# PIC16F1937 register map
File version: 1.0
Registers are 8-bit, read-write, reset 0x0 unless marked. A register's access mark holds for its fields unless they carry their own. Offsets are from the block's base; [hi:lo] are bit positions; {n}, {i} and the like mark numbered series.

## MSSP — Synchronous serial port
Base 0x00800211
0x00 SSPBUF reset not defined — SSPBUF, data address 0x211
0x01 SSPADD — SSPADD, data address 0x212
0x02 SSPMSK reset 0xFF — SSPMSK, data address 0x213
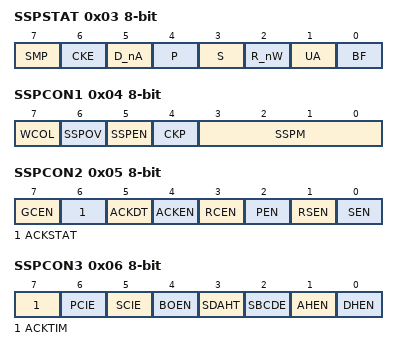
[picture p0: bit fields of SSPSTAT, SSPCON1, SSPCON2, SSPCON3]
0x03 SSPSTAT — SSPSTAT, data address 0x214
  [7] SMP, [6] CKE, [5] D_nA, [4] P, [3] S, [2] R_nW, [1] UA, [0] BF
0x04 SSPCON1 — SSPCON1, data address 0x215
  [7] WCOL, [6] SSPOV, [5] SSPEN, [4] CKP, [3:0] SSPM
0x05 SSPCON2 — SSPCON2, data address 0x216
  [7] GCEN, [6] ACKSTAT, [5] ACKDT, [4] ACKEN, [3] RCEN, [2] PEN, [1] RSEN, [0] SEN
0x06 SSPCON3 (reset mask 0x9F) — SSPCON3, data address 0x217
  [7] ACKTIM, [6] PCIE, [5] SCIE, [4] BOEN, [3] SDAHT, [2] SBCDE, [1] AHEN, [0] DHEN

## NVM — Flash and EEPROM access
Base 0x00800191
0x00 EEADRL — EEADRL, data address 0x191
0x01 EEADRH reset 0x80 — EEADRH, data address 0x192
  [6:0] EEADRH
0x02 EEDATL reset not defined — EEDATL, data address 0x193
0x03 EEDATH reset not defined — EEDATH, data address 0x194
  [5:0] EEDATH
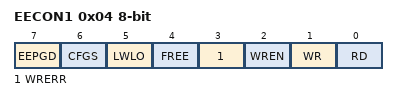
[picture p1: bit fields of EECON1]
0x04 EECON1 (reset mask 0xF7) — EECON1, data address 0x195
  [7] EEPGD, [6] CFGS, [5] LWLO, [4] FREE, [3] WRERR, [2] WREN, [1] WR, [0] RD
0x05 EECON2 reset not defined — EECON2, data address 0x196

## OSCILLATOR
Base 0x00800098
0x00 OSCTUNE — OSCTUNE, data address 0x098
  [5:0] TUN
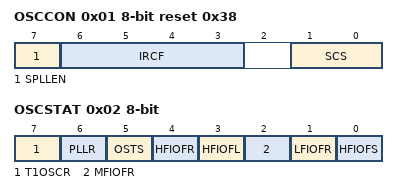
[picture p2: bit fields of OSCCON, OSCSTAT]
0x01 OSCCON reset 0x38 — OSCCON, data address 0x099
  [7] SPLLEN, [6:3] IRCF, [1:0] SCS
0x02 OSCSTAT (reset mask 0xDB) — OSCSTAT, data address 0x09a
  [7] T1OSCR, [6] PLLR, [5] OSTS, [4] HFIOFR, [3] HFIOFL, [2] MFIOFR, [1] LFIOFR, [0] HFIOFS

## PORTA
Base 0x0080000C
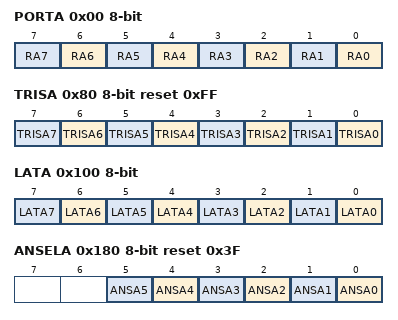
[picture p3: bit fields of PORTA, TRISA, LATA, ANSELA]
0x00 PORTA reset not defined — PORTA, data address 0x00c
  [n] RA{n} (n=0..7)
0x80 TRISA reset 0xFF — TRISA, data address 0x08c
  [n] TRISA{n} (n=0..7)
0x100 LATA reset not defined — LATA, data address 0x10c
  [n] LATA{n} (n=0..7)
0x180 ANSELA reset 0x3F — ANSELA, data address 0x18c
  [n] ANSA{n} (n=0..5)

## PORTB
Base 0x0080000D
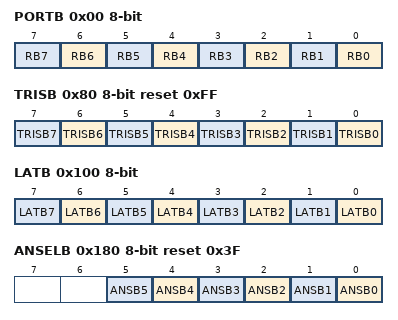
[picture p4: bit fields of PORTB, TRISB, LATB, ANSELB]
0x00 PORTB reset not defined — PORTB, data address 0x00d
  [n] RB{n} (n=0..7)
0x80 TRISB reset 0xFF — TRISB, data address 0x08d
  [n] TRISB{n} (n=0..7)
0x100 LATB reset not defined — LATB, data address 0x10d
  [n] LATB{n} (n=0..7)
0x180 ANSELB reset 0x3F — ANSELB, data address 0x18d
  [n] ANSB{n} (n=0..5)
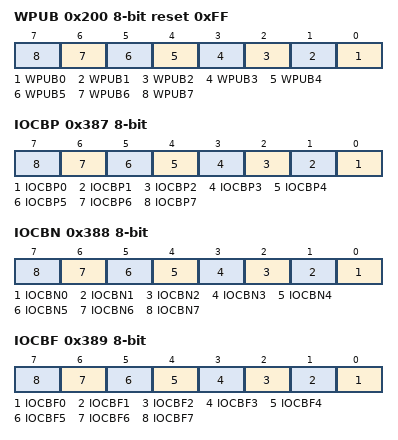
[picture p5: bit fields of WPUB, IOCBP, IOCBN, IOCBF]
0x200 WPUB reset 0xFF — WPUB, data address 0x20d
  [n] WPUB{n} (n=0..7)
0x387 IOCBP — IOCBP, data address 0x394
  [n] IOCBP{n} (n=0..7)
0x388 IOCBN — IOCBN, data address 0x395
  [n] IOCBN{n} (n=0..7)
0x389 IOCBF — IOCBF, data address 0x396
  [n] IOCBF{n} (n=0..7)

## PORTC
Base 0x0080000E
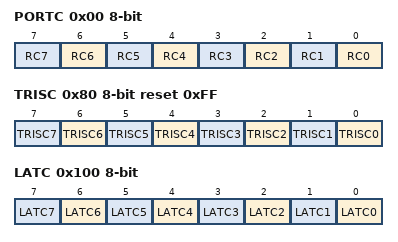
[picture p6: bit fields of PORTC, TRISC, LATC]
0x00 PORTC reset not defined — PORTC, data address 0x00e
  [n] RC{n} (n=0..7)
0x80 TRISC reset 0xFF — TRISC, data address 0x08e
  [n] TRISC{n} (n=0..7)
0x100 LATC reset not defined — LATC, data address 0x10e
  [n] LATC{n} (n=0..7)

## PORTD
Base 0x0080000F
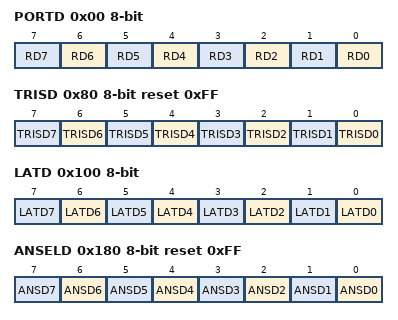
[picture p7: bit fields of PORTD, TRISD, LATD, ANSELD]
0x00 PORTD reset not defined — PORTD, data address 0x00f
  [n] RD{n} (n=0..7)
0x80 TRISD reset 0xFF — TRISD, data address 0x08f
  [n] TRISD{n} (n=0..7)
0x100 LATD reset not defined — LATD, data address 0x10f
  [n] LATD{n} (n=0..7)
0x180 ANSELD reset 0xFF — ANSELD, data address 0x18f
  [n] ANSD{n} (n=0..7)

## PORTE
Base 0x00800010
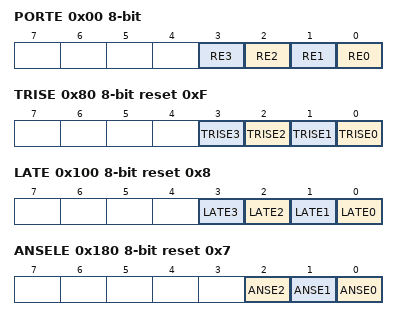
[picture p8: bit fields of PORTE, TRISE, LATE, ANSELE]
0x00 PORTE reset not defined — PORTE, data address 0x010
  [n] RE{n} (n=0..3)
0x80 TRISE reset 0xF — TRISE, data address 0x090
  [n] TRISE{n} (n=0..3)
0x100 LATE reset 0x8 (reset mask 0x8) — LATE, data address 0x110
  [n] LATE{n} (n=0..3)
0x180 ANSELE reset 0x7 — ANSELE, data address 0x190
  [2] ANSE2, [1] ANSE1, [0] ANSE0
0x200 WPUE reset 0x8 — WPUE, data address 0x210
  [3] WPUE3

## REFERENCES — Voltage reference, DAC and SR latch
Base 0x00800117
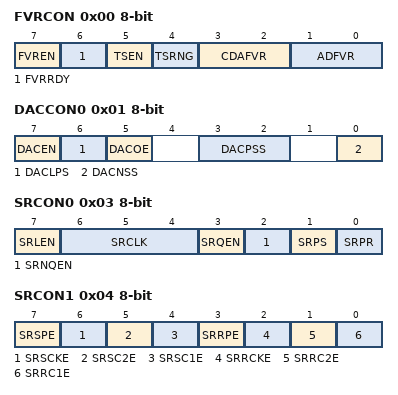
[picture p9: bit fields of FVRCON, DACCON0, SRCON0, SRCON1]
0x00 FVRCON (reset mask 0xBF) — FVRCON, data address 0x117
  [7] FVREN, [6] FVRRDY, [5] TSEN, [4] TSRNG, [3:2] CDAFVR, [1:0] ADFVR
0x01 DACCON0 — DACCON0, data address 0x118
  [7] DACEN, [6] DACLPS, [5] DACOE, [3:2] DACPSS, [0] DACNSS
0x02 DACCON1 — DACCON1, data address 0x119
  [4:0] DACR
0x03 SRCON0 — SRCON0, data address 0x11a
  [7] SRLEN, [6:4] SRCLK, [3] SRQEN, [2] SRNQEN, [1] SRPS, [0] SRPR
0x04 SRCON1 — SRCON1, data address 0x11b
  [7] SRSPE, [6] SRSCKE, [5] SRSC2E, [4] SRSC1E, [3] SRRPE, [2] SRRCKE, [1] SRRC2E, [0] SRRC1E

## SYSTEM — Reset, watchdog and pin options
Base 0x00800095
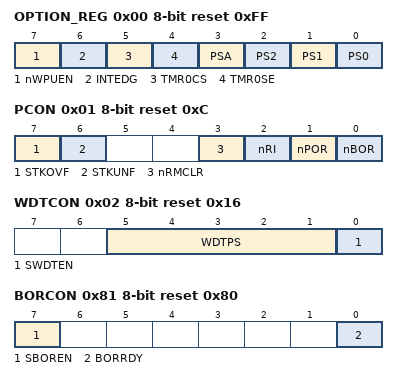
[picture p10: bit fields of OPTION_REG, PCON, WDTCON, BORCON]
0x00 OPTION_REG reset 0xFF — OPTION_REG, data address 0x095
  [7] nWPUEN, [6] INTEDG, [5] TMR0CS, [4] TMR0SE, [3] PSA, [2] PS2, [1] PS1, [0] PS0
0x01 PCON reset 0xC (reset mask 0xCC) — PCON, data address 0x096
  [7] STKOVF, [6] STKUNF, [3] nRMCLR, [2] nRI, [1] nPOR, [0] nBOR
0x02 WDTCON reset 0x16 — WDTCON, data address 0x097
  [5:1] WDTPS, [0] SWDTEN
0x81 BORCON reset 0x80 (reset mask 0x80) — BORCON, data address 0x116
  [7] SBOREN, [0] BORRDY
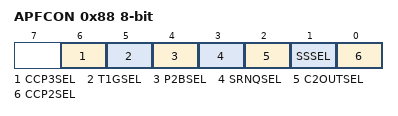
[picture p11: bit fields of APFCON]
0x88 APFCON — APFCON, data address 0x11d
  [6] CCP3SEL, [5] T1GSEL, [4] P2BSEL, [3] SRNQSEL, [2] C2OUTSEL, [1] SSSEL, [0] CCP2SEL

## TIMER0
Base 0x00800015
0x00 TMR0 reset not defined — TMR0, data address 0x015

## TIMER1
Base 0x00800016
0x00 TMR1L reset not defined — TMR1L, data address 0x016
0x01 TMR1H reset not defined — TMR1H, data address 0x017
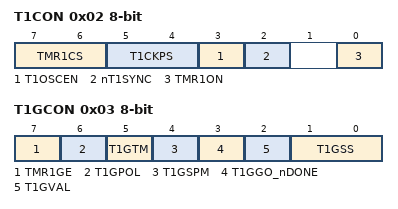
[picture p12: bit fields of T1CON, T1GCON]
0x02 T1CON — T1CON, data address 0x018
  [7:6] TMR1CS, [5:4] T1CKPS, [3] T1OSCEN, [2] nT1SYNC, [0] TMR1ON
0x03 T1GCON (reset mask 0xFB) — T1GCON, data address 0x019
  [7] TMR1GE, [6] T1GPOL, [5] T1GTM, [4] T1GSPM, [3] T1GGO_nDONE, [2] T1GVAL, [1:0] T1GSS

## TIMER2
Base 0x0080001A
0x00 TMR2 — TMR2, data address 0x01a
0x01 PR2 reset 0xFF — PR2, data address 0x01b
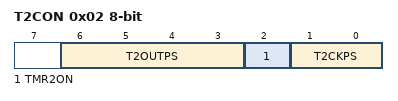
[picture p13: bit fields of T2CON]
0x02 T2CON — T2CON, data address 0x01c
  [6:3] T2OUTPS, [2] TMR2ON, [1:0] T2CKPS

## TIMER4
Base 0x00800415
0x00 TMR4 — TMR4, data address 0x415
0x01 PR4 reset 0xFF — PR4, data address 0x416
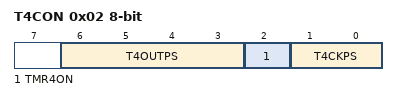
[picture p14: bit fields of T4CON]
0x02 T4CON — T4CON, data address 0x417
  [6:3] T4OUTPS, [2] TMR4ON, [1:0] T4CKPS

## TIMER6
Base 0x0080041C
0x00 TMR6 — TMR6, data address 0x41c
0x01 PR6 reset 0xFF — PR6, data address 0x41d
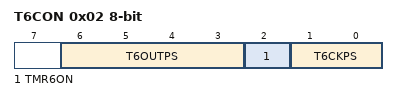
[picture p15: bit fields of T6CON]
0x02 T6CON — T6CON, data address 0x41e
  [6:3] T6OUTPS, [2] TMR6ON, [1:0] T6CKPS
